# STM32L0x0 register map
File version: 1.1
CPU: CM0+ r0p0, little endian, MPU, no FPU, 4 interrupt priority bits
Registers are 32-bit, read-write, reset 0x0 unless marked. A register's access mark holds for its fields unless they carry their own. Offsets are from the block's base; [hi:lo] are bit positions; {n}, {i} and the like mark numbered series.

## LPUART1 — Lower power Universal asynchronous receiver transmitter
Base 0x40004800
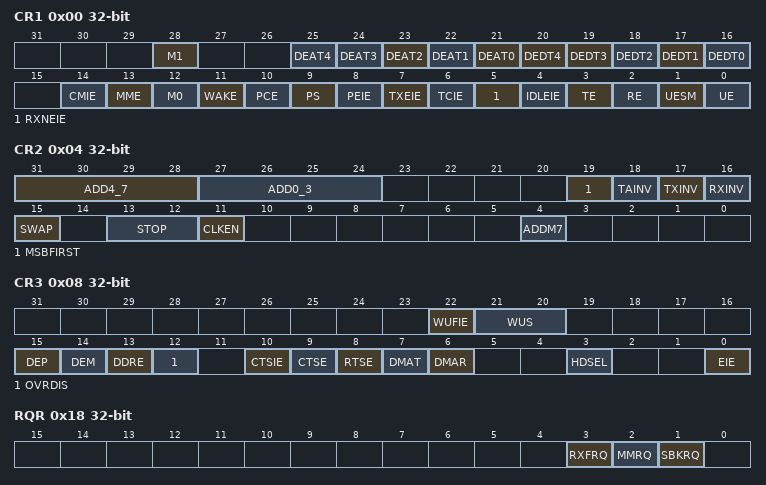
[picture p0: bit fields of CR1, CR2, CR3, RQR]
0x00 CR1 — Control register 1
  [28] M1 — Word length
  [25] DEAT4 — Driver Enable assertion time
  [n+21] DEAT{n} (n=0..3)
  [20] DEDT4 — Driver Enable de-assertion time
  [n+16] DEDT{n} (n=0..3)
  [14] CMIE — Character match interrupt enable
  [13] MME — Mute mode enable
  [12] M0 — Word length
  [11] WAKE — Receiver wakeup method
  [10] PCE — Parity control enable
  [9] PS — Parity selection
  [8] PEIE — PE interrupt enable
  [7] TXEIE — interrupt enable
  [6] TCIE — Transmission complete interrupt enable
  [5] RXNEIE — RXNE interrupt enable
  [4] IDLEIE — IDLE interrupt enable
  [3] TE — Transmitter enable
  [2] RE — Receiver enable
  [1] UESM — USART enable in Stop mode
  [0] UE — USART enable
0x04 CR2 — Control register 2
  [31:28] ADD4_7 — Address of the USART node
  [27:24] ADD0_3 — Address of the USART node
  [19] MSBFIRST — Most significant bit first
  [18] TAINV — Binary data inversion
  [17] TXINV — TX pin active level inversion
  [16] RXINV — RX pin active level inversion
  [15] SWAP — Swap TX/RX pins
  [13:12] STOP — STOP bits
  [11] CLKEN — Clock enable
  [4] ADDM7 — 7-bit Address Detection/4-bit Address Detection
0x08 CR3 — Control register 3
  [22] WUFIE — Wakeup from Stop mode interrupt enable
  [21:20] WUS — Wakeup from Stop mode interrupt flag selection
  [15] DEP — Driver enable polarity selection
  [14] DEM — Driver enable mode
  [13] DDRE — DMA Disable on Reception Error
  [12] OVRDIS — Overrun Disable
  [10] CTSIE — CTS interrupt enable
  [9] CTSE — CTS enable
  [8] RTSE — RTS enable
  [7] DMAT — DMA enable transmitter
  [6] DMAR — DMA enable receiver
  [3] HDSEL — Half-duplex selection
  [0] EIE — Error interrupt enable
0x0C BRR — Baud rate register
  [19:0] BRR
0x18 RQR wo — Request register
  [3] RXFRQ — Receive data flush request
  [2] MMRQ — Mute mode request
  [1] SBKRQ — Send break request
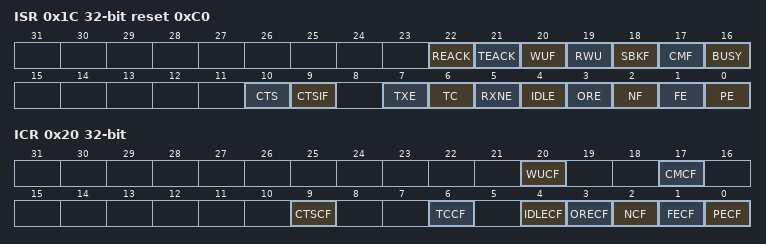
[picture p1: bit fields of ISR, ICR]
0x1C ISR ro reset 0xC0 — Interrupt & status register
  [22] REACK, [21] TEACK, [20] WUF, [19] RWU, [18] SBKF, [17] CMF, [16] BUSY, [10] CTS, [9] CTSIF, [7] TXE, [6] TC, [5] RXNE, [4] IDLE, [3] ORE, [2] NF, [1] FE, [0] PE
0x20 ICR wo — Interrupt flag clear register
  [20] WUCF — Wakeup from Stop mode clear flag
  [17] CMCF — Character match clear flag
  [9] CTSCF — CTS clear flag
  [6] TCCF — Transmission complete clear flag
  [4] IDLECF — Idle line detected clear flag
  [3] ORECF — Overrun error clear flag
  [2] NCF — Noise detected clear flag
  [1] FECF — Framing error clear flag
  [0] PECF — Parity error clear flag
0x24 RDR ro — Receive data register
  [8:0] RDR — Receive data value
0x28 TDR — Transmit data register
  [8:0] TDR — Transmit data value

## NVIC — Nested Vectored Interrupt Controller
Base 0xE000E100
0x00 ISER — Interrupt Set Enable Register
  [31:0] SETENA
0x80 ICER — Interrupt Clear Enable Register
  [31:0] CLRENA
0x100 ISPR — Interrupt Set-Pending Register
  [31:0] SETPEND
0x180 ICPR — Interrupt Clear-Pending Register
  [31:0] CLRPEND
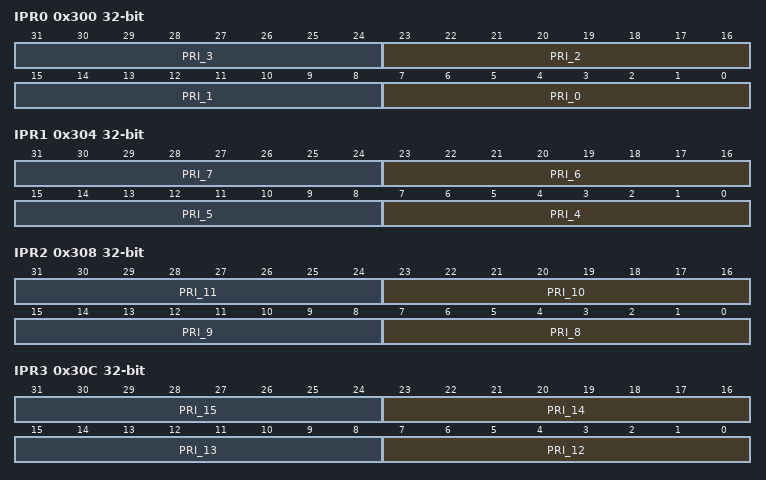
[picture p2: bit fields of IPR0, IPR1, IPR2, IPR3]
0x300 IPR0 — Interrupt Priority Register 0
  [8n+7:8n] PRI_{n} (n=0..3) — priority for interrupt {n}
0x304 IPR1 — Interrupt Priority Register 1
  [8n-25:8n-32] PRI_{n} (n=4..7) — priority for interrupt n
0x308 IPR2 — Interrupt Priority Register 2
  [8n-57:8n-64] PRI_{n} (n=8..11) — priority for interrupt n
0x30C IPR3 — Interrupt Priority Register 3
  [8n-89:8n-96] PRI_{n} (n=12..15) — priority for interrupt n
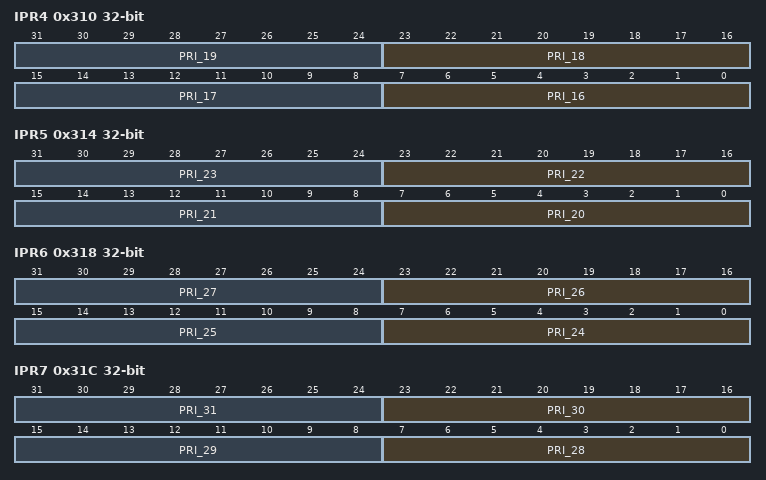
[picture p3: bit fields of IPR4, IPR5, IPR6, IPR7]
0x310 IPR4 — Interrupt Priority Register 4
  [8n-121:8n-128] PRI_{n} (n=16..19) — priority for interrupt n
0x314 IPR5 — Interrupt Priority Register 5
  [8n-153:8n-160] PRI_{n} (n=20..23) — priority for interrupt n
0x318 IPR6 — Interrupt Priority Register 6
  [8n-185:8n-192] PRI_{n} (n=24..27) — priority for interrupt n
0x31C IPR7 — Interrupt Priority Register 7
  [8n-217:8n-224] PRI_{n} (n=28..31) — priority for interrupt n

## MPU — Memory protection unit
Base 0xE000ED90
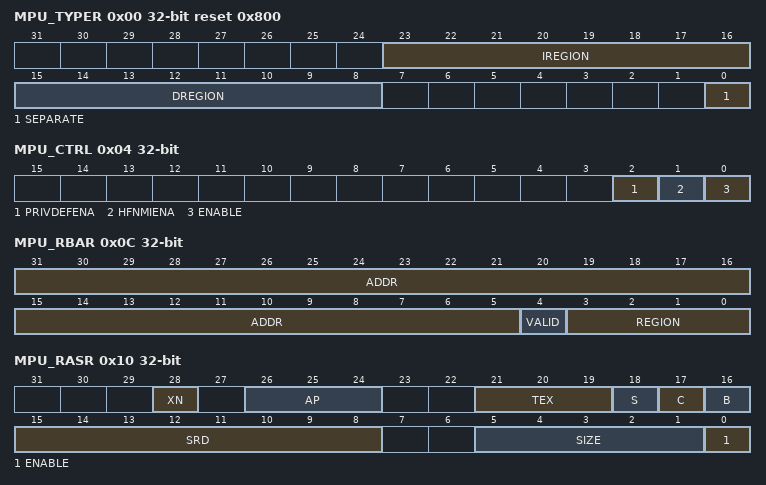
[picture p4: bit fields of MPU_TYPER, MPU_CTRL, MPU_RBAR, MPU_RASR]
0x00 MPU_TYPER ro reset 0x800 — MPU type register
  [23:16] IREGION — Number of MPU instruction regions
  [15:8] DREGION — Number of MPU data regions
  [0] SEPARATE — Separate flag
0x04 MPU_CTRL — MPU control register
  [2] PRIVDEFENA — Enable priviliged software access to default memory map
  [1] HFNMIENA — Enables the operation of MPU during hard fault
  [0] ENABLE — Enables the MPU
0x08 MPU_RNR — MPU region number register
  [7:0] REGION — MPU region
0x0C MPU_RBAR — MPU region base address register
  [31:5] ADDR — Region base address field
  [4] VALID — MPU region number valid
  [3:0] REGION — MPU region field
0x10 MPU_RASR — MPU region attribute and size register
  [28] XN — Instruction access disable bit
  [26:24] AP — Access permission
  [21:19] TEX — memory attribute
  [18] S — Shareable memory attribute
  [17] C — memory attribute
  [16] B — memory attribute
  [15:8] SRD — Subregion disable bits
  [5:1] SIZE — Size of the MPU protection region
  [0] ENABLE — Region enable bit.

## STK — SysTick timer
Base 0xE000E010
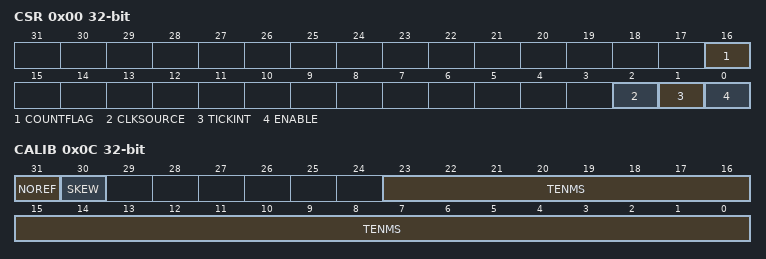
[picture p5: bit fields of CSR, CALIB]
0x00 CSR — SysTick control and status register
  [16] COUNTFLAG
  [2] CLKSOURCE — Clock source selection
  [1] TICKINT — SysTick exception request enable
  [0] ENABLE — Counter enable
0x04 RVR — SysTick reload value register
  [23:0] RELOAD — RELOAD value
0x08 CVR — SysTick current value register
  [23:0] CURRENT — Current counter value
0x0C CALIB — SysTick calibration value register
  [31] NOREF — NOREF flag. Reads as zero
  [30] SKEW — SKEW flag: Indicates whether the TENMS value is exact
  [23:0] TENMS — Calibration value

## SCB — System control block
Base 0xE000ED00
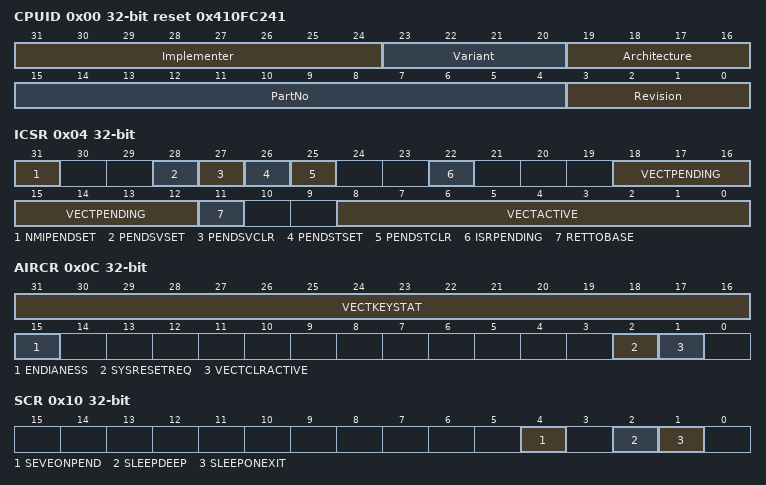
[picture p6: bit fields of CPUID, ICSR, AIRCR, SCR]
0x00 CPUID ro reset 0x410FC241 — CPUID base register
  [31:24] Implementer — Implementer code
  [23:20] Variant — Variant number
  [19:16] Architecture — Reads as 0xF
  [15:4] PartNo — Part number of the processor
  [3:0] Revision — Revision number
0x04 ICSR — Interrupt control and state register
  [31] NMIPENDSET — NMI set-pending bit.
  [28] PENDSVSET — PendSV set-pending bit
  [27] PENDSVCLR — PendSV clear-pending bit
  [26] PENDSTSET — SysTick exception set-pending bit
  [25] PENDSTCLR — SysTick exception clear-pending bit
  [22] ISRPENDING — Interrupt pending flag
  [18:12] VECTPENDING — Pending vector
  [11] RETTOBASE — Return to base level
  [8:0] VECTACTIVE — Active vector
0x08 VTOR — Vector table offset register
  [31:7] TBLOFF — Vector table base offset field
0x0C AIRCR — Application interrupt and reset control register
  [31:16] VECTKEYSTAT — Register key
  [15] ENDIANESS
  [2] SYSRESETREQ
  [1] VECTCLRACTIVE
0x10 SCR — System control register
  [4] SEVEONPEND — Send Event on Pending bit
  [2] SLEEPDEEP
  [1] SLEEPONEXIT
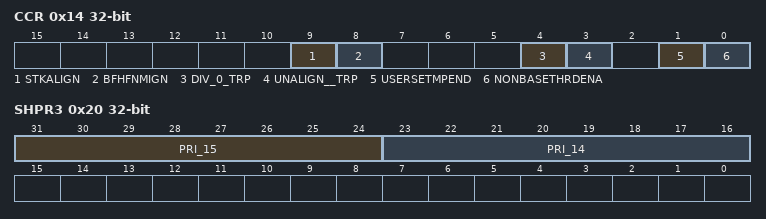
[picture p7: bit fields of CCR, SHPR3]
0x14 CCR — Configuration and control register
  [9] STKALIGN
  [8] BFHFNMIGN
  [4] DIV_0_TRP
  [3] UNALIGN__TRP
  [1] USERSETMPEND
  [0] NONBASETHRDENA — Configures how the processor enters Thread mode
0x1C SHPR2 — System handler priority registers
  [31:24] PRI_11 — Priority of system handler 11
0x20 SHPR3 — System handler priority registers
  [31:24] PRI_15 — Priority of system handler 15
  [23:16] PRI_14 — Priority of system handler 14
